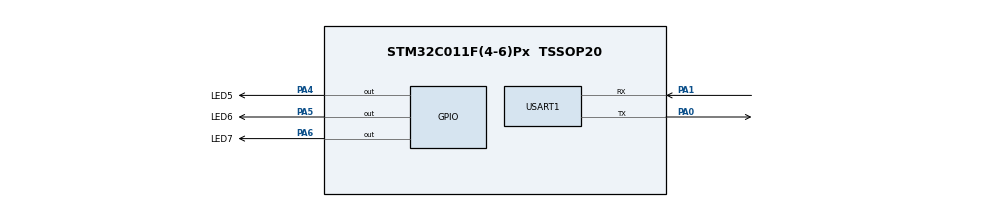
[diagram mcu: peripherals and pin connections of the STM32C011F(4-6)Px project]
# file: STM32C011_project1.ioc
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Mcu.Family=STM32C0
Mcu.Name=STM32C011F(4-6)Px
Mcu.Package=TSSOP20
PA0.Mode=Asynchronous
PA0.Signal=USART1_TX
PA1.Mode=Asynchronous
PA1.Signal=USART1_RX
PA4.GPIO_Label=LED5
PA4.Signal=GPIO_Output
PA5.GPIO_Label=LED6
PA5.Signal=GPIO_Output
PA6.GPIO_Label=LED7
PA6.Signal=GPIO_Output
ProjectManager.HeapSize=0x400
ProjectManager.StackSize=0x800
ProjectManager.TargetToolchain=MDK-ARM V5.37
RCC.ADCFreq_Value=48000000
RCC.AHBFreq_Value=48000000
RCC.CortexFreq_Value=48000000
RCC.EXTERNAL_CLOCK_VALUE=12288000
RCC.HCLKFreq_Value=48000000
RCC.HSE_VALUE=8000000
RCC.HSISYSCLKDivider=RCC_HSI_DIV1
RCC.HSI_VALUE=48000000
RCC.LSE_VALUE=32768
RCC.SYSCLKFreq_VALUE=48000000
USART1.VirtualMode-Asynchronous=VM_ASYNC
board=custom

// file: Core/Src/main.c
/* USER CODE BEGIN Header */
/**
  ******************************************************************************
  * @file           : main.c
  * @brief          : Main program body
  ******************************************************************************
  * @attention
  *
  * Copyright (c) 2024 STMicroelectronics.
  * All rights reserved.
  *
  * This software is licensed under terms that can be found in the LICENSE file
  * in the root directory of this software component.
  * If no LICENSE file comes with this software, it is provided AS-IS.
  *
  ******************************************************************************
  */
/* USER CODE END Header */
#include "main.h"
#include "usart.h"
#include "gpio.h"

/* USER CODE BEGIN Includes */
#include "stdio.h"
/* USER CODE END Includes */

void SystemClock_Config(void);
/* USER CODE BEGIN PFP */
int fputc(int ch, FILE *f){
	HAL_UART_Transmit(&huart1 , (uint8_t *)&ch, 1, 0xFFFF);
	return ch;
}
/* USER CODE END PFP */

int main(void)
{

  /* MCU Configuration--------------------------------------------------------*/

  /* Reset of all peripherals, Initializes the Flash interface and the Systick. */
  HAL_Init();

  /* Configure the system clock */
  SystemClock_Config();

  /* Initialize all configured peripherals */
  MX_GPIO_Init();
  MX_USART1_UART_Init();

  /* Infinite loop */
  /* USER CODE BEGIN WHILE */
  while (1)
  {
		HAL_GPIO_WritePin(LED5_GPIO_Port, LED5_Pin, GPIO_PIN_SET);
		HAL_GPIO_WritePin(LED6_GPIO_Port, LED6_Pin, GPIO_PIN_SET);
		HAL_GPIO_WritePin(LED7_GPIO_Port, LED7_Pin, GPIO_PIN_SET);
		printf("LED ON!\n");
		HAL_Delay(1000);
		HAL_GPIO_WritePin(LED5_GPIO_Port, LED5_Pin, GPIO_PIN_RESET);
		HAL_GPIO_WritePin(LED6_GPIO_Port, LED6_Pin, GPIO_PIN_RESET);
		HAL_GPIO_WritePin(LED7_GPIO_Port, LED7_Pin, GPIO_PIN_RESET);
		printf("LED OFF!\n");
		HAL_Delay(1000);

    /* USER CODE END WHILE */

  }
}

void SystemClock_Config(void)
{
  RCC_OscInitTypeDef RCC_OscInitStruct = {0};
  RCC_ClkInitTypeDef RCC_ClkInitStruct = {0};

  /** Initializes the RCC Oscillators according to the specified parameters
  * in the RCC_OscInitTypeDef structure.
  */
  RCC_OscInitStruct.OscillatorType = RCC_OSCILLATORTYPE_HSI;
  RCC_OscInitStruct.HSIState = RCC_HSI_ON;
  RCC_OscInitStruct.HSIDiv = RCC_HSI_DIV1;
  RCC_OscInitStruct.HSICalibrationValue = RCC_HSICALIBRATION_DEFAULT;
  if (HAL_RCC_OscConfig(&RCC_OscInitStruct) != HAL_OK)
  {
    Error_Handler();
  }

  /** Initializes the CPU, AHB and APB buses clocks
  */
  RCC_ClkInitStruct.ClockType = RCC_CLOCKTYPE_HCLK|RCC_CLOCKTYPE_SYSCLK
                              |RCC_CLOCKTYPE_PCLK1;
  RCC_ClkInitStruct.SYSCLKSource = RCC_SYSCLKSOURCE_HSI;
  RCC_ClkInitStruct.SYSCLKDivider = RCC_SYSCLK_DIV1;
  RCC_ClkInitStruct.AHBCLKDivider = RCC_HCLK_DIV1;
  RCC_ClkInitStruct.APB1CLKDivider = RCC_APB1_DIV1;

  if (HAL_RCC_ClockConfig(&RCC_ClkInitStruct, FLASH_LATENCY_1) != HAL_OK)
  {
    Error_Handler();
  }
}

void Error_Handler(void)
{
  __disable_irq();
  while (1)
  {
  }
}
